# LKS32MC08x register map
Vendor: Linko Ltd.; Series: LKS32MC08x; File version: 1.0
CPU: CM0 r1p0, little endian, MPU, no FPU, 3 interrupt priority bits
Registers are 32-bit, read-write, reset 0x0 unless marked. A register's access mark holds for its fields unless they carry their own. Offsets are from the block's base; [hi:lo] are bit positions; {n}, {i} and the like mark numbered series; 'fields as' and 'values as' point back to an identical list.

## SYS — SYS registers
Base 0x40000000
0x08 SYS_WDT_PSW wo — WatchDog Password
0x0C SYS_WDT_CLR wo — WatchDog feed
0x10 SYS_AFE_ADC0 ro — ADC data for test
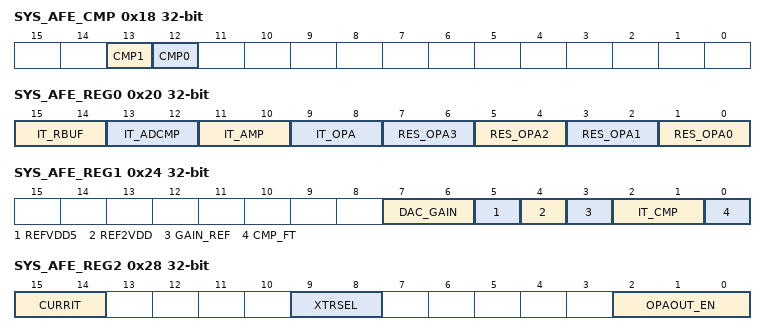
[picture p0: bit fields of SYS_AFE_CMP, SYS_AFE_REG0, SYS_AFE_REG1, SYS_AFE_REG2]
0x18 SYS_AFE_CMP ro — Comparator output for test
  [13] CMP1 — Comparator 1 output
  [12] CMP0 — Comparator 0 output
0x20 SYS_AFE_REG0 — Analog reg0
  [15:14] IT_RBUF — ADC reference buffer bias select
    0=1P0 (1 times); 1=1P2 (1.2 times); 2=1P5 (1.5 times); 3=2P0 (2 times)
  [13:12] IT_ADCMP — ADC CMP bias select
    0=1P0 (1 times); 1=2P0 (2 times); 2=0P66 (0.66 times); 3=1P00 (1 times)
  [11:10] IT_AMP — ADC AMP bias select
    0=1P0 (1 times); 1=1P5 (1.5 times); 2=1P75 (1.75 times); 3=1P00 (1 times)
  [9:8] IT_OPA — OPA bias select
    values as IT_RBUF
  [2n+1:2n] RES_OPA{n} (n=0..3) — OPA{n} feedback resistor
    0=200k_10k; 1=190k_20k; 2=180k_30k; 3=170k_40k
0x24 SYS_AFE_REG1 — Analog reg1
  [7:6] DAC_GAIN
  [5] REFVDD5 — OPA output range
  [4] REF2VDD — Use external ADC ref
  [3] GAIN_REF — ADC ref select
    0=2 times; 1=1 times
  [2:1] IT_CMP — Comparator bias select
  [0] CMP_FT — Comparator fast mode
0x28 SYS_AFE_REG2 — Analog reg2
  [15:14] CURRIT — ADC global bias select
    0=N0P33 (-0.33); 1=1P0; 2=N0P66 (-0.66); 3=N0P75 (-0.75)
  [9:8] XTRSEL — crystal oscillator resistor select
  [2:0] OPAOUT_EN — OPA output enable
    0=None (No output); {v}=OPA{v-1} (OPA{v-1} output to P2[7]) (v=1..4)
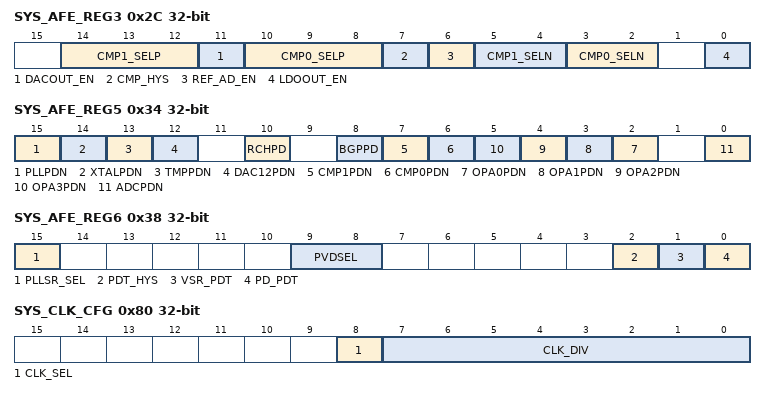
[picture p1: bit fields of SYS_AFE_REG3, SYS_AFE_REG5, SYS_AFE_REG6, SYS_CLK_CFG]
0x2C SYS_AFE_REG3 — Analog reg3
  [14:12] CMP1_SELP — Comparator 1 positive input select
    0=CMP1_IP0; 1=OPA3_IP; 2=OPA2_OUT; 3=OPA3_OUT; 4=CMP1_IP1; 5=CMP1_IP2; 6=CMP1_IP3; 7=AVSS
  [11] DACOUT_EN — DAC output enable
    0=DISABLED (DAC output disabled); 1=ENABLED (DAC output to P0[0])
  [10:8] CMP0_SELP — Comparator 0 positive input select
    0=CMP0_IP0; 1=OPA0_IP; 2=OPA0_OUT; 3=OPA1_OUT; {v}=CMP0_IP{v-3} (v=4..7)
  [7] CMP_HYS — Comparator hystersis select
    0=20mV; 1=0mV
  [6] REF_AD_EN — ADC REF output enable
    0=DISABLED (ADC REF output disabled); 1=ENABLED (ADC REF output toP2[3])
  [5:4] CMP1_SELN — Comparator 1 negative input select
    0=CMP1_IN; 1=REF; 2=DACOUT; 3=HALL1_MID
  [3:2] CMP0_SELN — Comparator 0 negative input select
    0=CMP0_IN; 1=REF; 2=DACOUT; 3=HALL0_MID
  [0] LDOOUT_EN — LDO output enable
    0=DISABLED (LDO output disabled); 1=ENABLED (LDO output toP2[7])
0x30 SYS_AFE_REG4 — Analog reg4
0x34 SYS_AFE_REG5 — Analog reg5
  [15] PLLPDN — PLL power down
    0=OFF (OFF(Default)); 1=ON
  [14] XTALPDN — Xtal power down
    0=OFF (OFF(Default)); 1=ON
  [13] TMPPDN — Temp sensor power down
    0=OFF (OFF(Default)); 1=ON
  [12] DAC12PDN — DAC power down
    0=OFF (OFF(Default)); 1=ON
  [10] RCHPD — RC power down
    0=ON (ON(Default)); 1=OFF
  [8] BGPPD — Bandgap power down
    0=ON (ON(Default)); 1=OFF
  [7] CMP1PDN — Comparator 1 power down
    0=OFF (OFF(Default)); 1=ON
  [6] CMP0PDN — Comparator 0 power down
    0=OFF (OFF(Default)); 1=ON
  [n+2] OPA{n}PDN (n=0..3) — OPA {n} power down
    0=OFF (OFF(Default)); 1=ON
  [0] ADCPDN — ADC power down
    0=OFF (OFF(Default)); 1=ON
0x38 SYS_AFE_REG6 — Analog reg6
  [15] PLLSR_SEL — PLL clock source select
    0=RCH (Use RCH as PLL clock source); 1=XTAL (Use external Xtal as PLL clock source)
  [9:8] PVDSEL — Power down threshold
    0=4P8; 1=4P5; 2=4P2; 3=3P9
  [2] PDT_HYS — Power down hystersis
    0=ON (ON(Default)); 1=OFF
  [1] VSR_PDT — Power down reference select
    0=1P3 (Use 1.3V as power down reference); 1=DACOUT (Use DAC output as power down reference)
  [0] PD_PDT — Power down disable
    0=ENABLED (Power down circuit is enabled); 1=DISABLED (Power down circuit is disabled)
0x3C SYS_AFE_REG7 — Analog reg7
  [5:4] ADCLKSEL — ADC clock select
    0=48MHz; 1=96MHz; 2=12MHz; 3=24MHz
0x7C SYS_AFE_DAC — DAC digital input
  [11:0] DAC_IN — DAC digital input value
0x80 SYS_CLK_CFG — Clock configuration
  [8] CLK_SEL — Select PLL or HRC as system clock
    0=HRC (Use 4MHz HRC as system clock); 1=PLL (Use PLL clock as system clock)
  [7:0] CLK_DIV — Clock enable of every 8 cycles
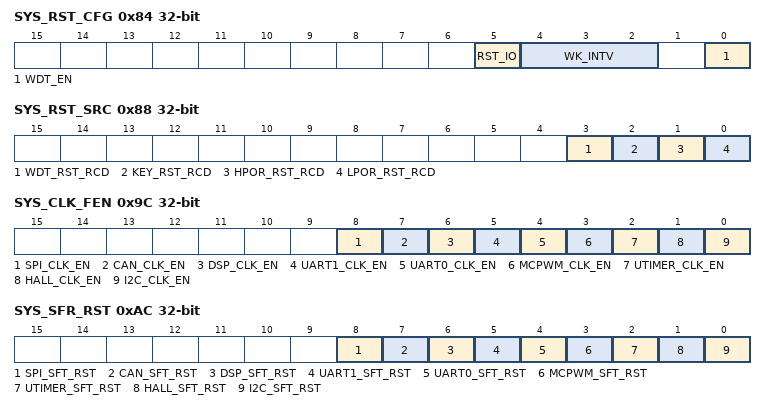
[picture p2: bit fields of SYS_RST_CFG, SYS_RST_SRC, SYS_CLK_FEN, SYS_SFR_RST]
0x84 SYS_RST_CFG — reset configuration
  [5] RST_IO — Use RSTn as GPIO
    0=DISABLED (As RSTn); 1=ENABLED (As GPIO)
  [4:2] WK_INTV — Wakeup interval
    0=0P25S (0.25s); 1=0P50S (0.5s); 2=1S; 3=2S; 4=4S; 5=8S; 6=16S; 7=32S
  [0] WDT_EN — WatchDog enable
    0=DISABLED (WDT is disabled); 1=ENABLED (WDT is enabled)
0x88 SYS_RST_SRC ro — reset source record
  [3] WDT_RST_RCD — Watchdog reset record
  [2] KEY_RST_RCD — Key reset record
  [1] HPOR_RST_RCD — HPOR record
  [0] LPOR_RST_RCD — LPOR record
0x8C SYS_CLR_RST wo — reset source record
  [15:0] RST_RCD_CLR — Write 0xCA40 to clear reset record
0x90 SYS_CLK_DIV0 — I2C Clock division ratio
  [15:0] I2C_CLK_DIV — I2C_CLK=MCLK/(CLK_DIV0+1)
0x98 SYS_CLK_DIV2 — UART Clock division ratio
  [15:0] UART_CLK_DIV — UART0/1_CLK=MCLK/(CLK_DIV2+1)
0x9C SYS_CLK_FEN — Peripheral clock enable
  [all] fields
    0=DISABLED (Clock is disabled); 1=ENABLED (Clock is enabled)
  [8] SPI_CLK_EN — SPI module clock enable
  [7] CAN_CLK_EN — CAN module clock enable
  [6] DSP_CLK_EN — DSP module clock enable
  [5] UART1_CLK_EN — UART1 module clock enable
  [4] UART0_CLK_EN — UART0 module clock enable
  [3] MCPWM_CLK_EN — MCPWM module clock enable
  [2] UTIMER_CLK_EN — Utimer module clock enable
  [1] HALL_CLK_EN — Hall module clock enable
  [0] I2C_CLK_EN — I2C module clock enable
0xA0 SYS_CLK_SLP wo — Sleep mode entry
  [15:0] SLP_ENTRY — Write 0xDEAD to enter sleep mode
0xA8 SYS_TRIM ro — System trim
0xAC SYS_SFR_RST — Peripheral soft reset
  [all] fields
    0=RELEASE (reset release); 1=RESET
  [8] SPI_SFT_RST — SPI module soft reset
  [7] CAN_SFT_RST — CAN module soft reset
  [6] DSP_SFT_RST — DSP module soft reset
  [5] UART1_SFT_RST — UART1 module soft reset
  [4] UART0_SFT_RST — UART0 module soft reset
  [3] MCPWM_SFT_RST — MCPWM module soft reset
  [2] UTIMER_SFT_RST — Utimer module soft reset
  [1] HALL_SFT_RST — Hall module soft reset
  [0] I2C_SFT_RST — I2C module soft reset
0xB0 SYS_PROTECT wo — System reg protect
  [15:0] SYS_REG_PROT — Write 0x7A83 to unlock protect
0xB4 SYS_AFE_DAC_AMC — DAC amplication calibration
0xB8 SYS_AFE_DAC_DC — DAC DC offset
